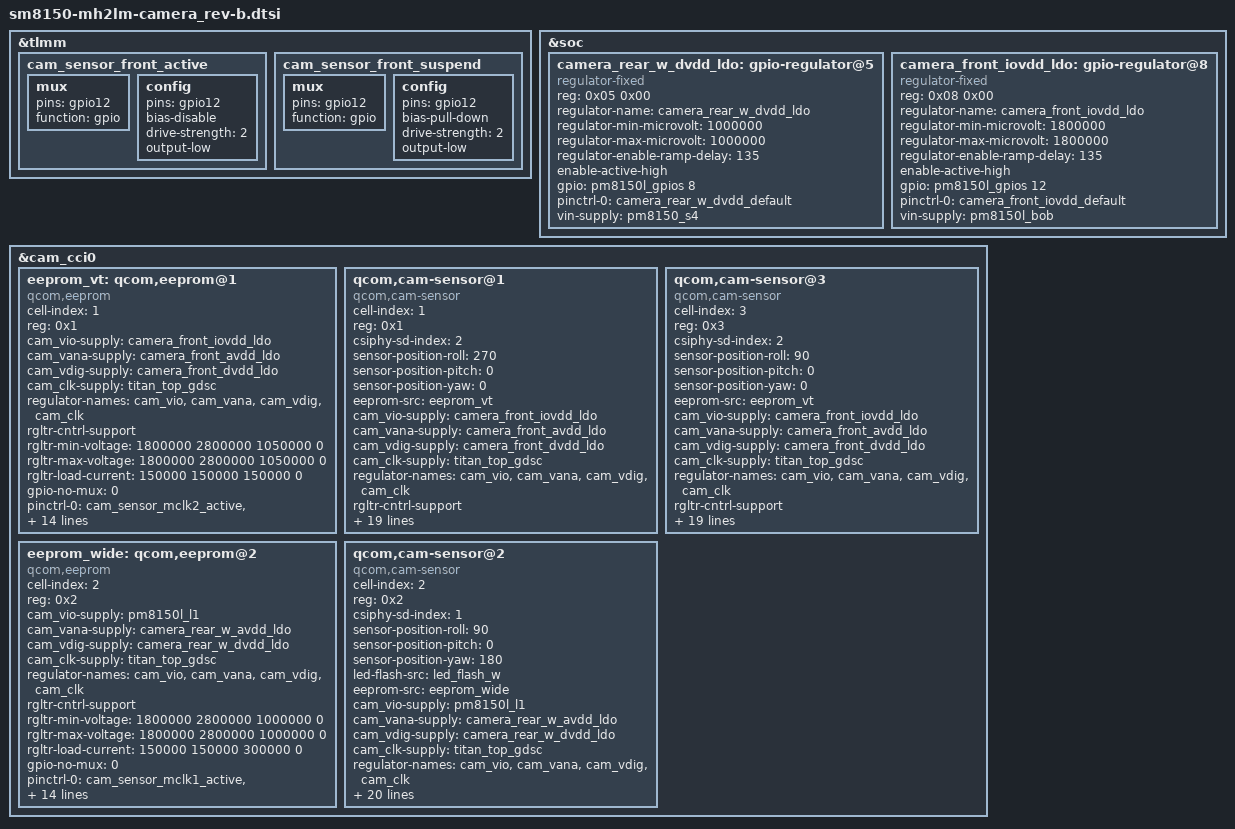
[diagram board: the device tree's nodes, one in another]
/*
 * Copyright (c) 2018, The Linux Foundation. All rights reserved.
 *
 * This program is free software; you can redistribute it and/or modify
 * it under the terms of the GNU General Public License version 2 and
 * only version 2 as published by the Free Software Foundation.
 *
 * This program is distributed in the hope that it will be useful,
 * but WITHOUT ANY WARRANTY; without even the implied warranty of
 * MERCHANTABILITY or FITNESS FOR A PARTICULAR PURPOSE.  See the
 * GNU General Public License for more details.
 */

#include "sm8150-mh2lm-camera_common.dtsi"

&tlmm {
	cam_sensor_front_active: cam_sensor_front_active {
		mux {
			pins = "gpio12";
			function = "gpio";
		};

		config {
			pins = "gpio12";
			bias-disable;
			drive-strength = <2>;
			output-low;
		};
	};

	cam_sensor_front_suspend: cam_sensor_front_suspend {
		mux {
			pins = "gpio12";
			function = "gpio";
		};

		config {
			pins = "gpio12";
			bias-pull-down;
			drive-strength = <2>;
			output-low;
		};
	};
};

&soc {
	camera_rear_w_dvdd_ldo: gpio-regulator@5 {
		compatible = "regulator-fixed";
		reg = <0x05 0x00>;
		regulator-name = "camera_rear_w_dvdd_ldo";
		regulator-min-microvolt = <1000000>;
		regulator-max-microvolt = <1000000>;
		regulator-enable-ramp-delay = <135>;
		enable-active-high;
		gpio = <&pm8150l_gpios 8 0>;
		pinctrl-names = "default";
		pinctrl-0 = <&camera_rear_w_dvdd_default>;
		vin-supply = <&pm8150_s4>;
	};

	camera_front_iovdd_ldo: gpio-regulator@8 {
		compatible = "regulator-fixed";
		reg = <0x08 0x00>;
		regulator-name = "camera_front_iovdd_ldo";
		regulator-min-microvolt = <1800000>;
		regulator-max-microvolt = <1800000>;
		regulator-enable-ramp-delay = <135>;
		enable-active-high;
		gpio = <&pm8150l_gpios 12 0>;
		pinctrl-names = "default";
		pinctrl-0 = <&camera_front_iovdd_default>;
		vin-supply = <&pm8150l_bob>;
	};
};

&cam_cci0 {
	eeprom_vt: qcom,eeprom@1 {
		cell-index = <1>;
		reg = <0x1>;
		compatible = "qcom,eeprom";
		cam_vio-supply =  <&camera_front_iovdd_ldo>;
		cam_vana-supply = <&camera_front_avdd_ldo>;
		cam_vdig-supply = <&camera_front_dvdd_ldo>;
		cam_clk-supply = <&titan_top_gdsc>;
		regulator-names = "cam_vio", "cam_vana", "cam_vdig", "cam_clk";
		rgltr-cntrl-support;
		rgltr-min-voltage = <1800000 2800000 1050000 0>;
		rgltr-max-voltage = <1800000 2800000 1050000 0>;
		rgltr-load-current = <150000 150000 150000 0>;
		gpio-no-mux = <0>;
		pinctrl-names = "cam_default", "cam_suspend";
		pinctrl-0 = <&cam_sensor_mclk2_active
				 &cam_sensor_front_active>;
		pinctrl-1 = <&cam_sensor_mclk2_suspend
				 &cam_sensor_front_suspend>;
		gpios = <&tlmm 15 0>,
			<&tlmm 12 0>;
		gpio-reset = <1>;
		gpio-req-tbl-num = <0 1>;
		gpio-req-tbl-flags = <1 0>;
		gpio-req-tbl-label = "VT_MCLK",
					"VT_RESET";
		sensor-mode = <0>;
		cci-device = <1>;
		cci-master = <0>;
		status = "ok";
		clocks = <&clock_camcc CAM_CC_MCLK2_CLK>;
		clock-names = "cam_clk";
		clock-cntl-level = "turbo";
		clock-rates = <19200000>;
    };

	qcom,cam-sensor@1 {
		cell-index = <1>;
		compatible = "qcom,cam-sensor";
		reg = <0x1>;
		csiphy-sd-index = <2>;
		sensor-position-roll = <270>;
		sensor-position-pitch = <0>;
		sensor-position-yaw = <0>;
		eeprom-src = <&eeprom_vt>;
		cam_vio-supply =  <&camera_front_iovdd_ldo>;
		cam_vana-supply = <&camera_front_avdd_ldo>;
		cam_vdig-supply = <&camera_front_dvdd_ldo>;
		cam_clk-supply = <&titan_top_gdsc>;
		regulator-names = "cam_vio", "cam_vana", "cam_vdig", "cam_clk";
		rgltr-cntrl-support;
		rgltr-min-voltage = <1800000 2800000 1050000 0>;
		rgltr-max-voltage = <1800000 2800000 1050000 0>;
		rgltr-load-current = <150000 150000 150000 0>;
		gpio-no-mux = <0>;
		pinctrl-names = "cam_default", "cam_suspend";
		pinctrl-0 = <&cam_sensor_mclk2_active
				 &cam_sensor_front_active>;
		pinctrl-1 = <&cam_sensor_mclk2_suspend
				 &cam_sensor_front_suspend>;
		gpios = <&tlmm 15 0>,
			<&tlmm 12 0>;
		gpio-reset = <1>;
		gpio-req-tbl-num = <0 1>;
		gpio-req-tbl-flags = <1 0>;
		gpio-req-tbl-label = "VT_MCLK",
					"VT_RESET";
		sensor-mode = <0>;
		cci-device = <1>;
		cci-master = <0>;
		status = "ok";
		clocks = <&clock_camcc CAM_CC_MCLK2_CLK>;
		clock-names = "cam_clk";
		clock-cntl-level = "turbo";
		clock-rates = <19200000>;
	};

	qcom,cam-sensor@3 {
		cell-index = <3>;
		compatible = "qcom,cam-sensor";
		reg = <0x3>;
		csiphy-sd-index = <2>;
		sensor-position-roll = <90>;
		sensor-position-pitch = <0>;
		sensor-position-yaw = <0>;
		eeprom-src = <&eeprom_vt>;
		cam_vio-supply =  <&camera_front_iovdd_ldo>;
		cam_vana-supply = <&camera_front_avdd_ldo>;
		cam_vdig-supply = <&camera_front_dvdd_ldo>;
		cam_clk-supply = <&titan_top_gdsc>;
		regulator-names = "cam_vio", "cam_vana", "cam_vdig", "cam_clk";
		rgltr-cntrl-support;
		rgltr-min-voltage = <1800000 2800000 1050000 0>;
		rgltr-max-voltage = <1800000 2800000 1050000 0>;
		rgltr-load-current = <150000 150000 150000 0>;
		gpio-no-mux = <0>;
		pinctrl-names = "cam_default", "cam_suspend";
		pinctrl-0 = <&cam_sensor_mclk2_active
				 &cam_sensor_front_active>;
		pinctrl-1 = <&cam_sensor_mclk2_suspend
				 &cam_sensor_front_suspend>;
		gpios = <&tlmm 15 0>,
			<&tlmm 12 0>;
		gpio-reset = <1>;
		gpio-req-tbl-num = <0 1>;
		gpio-req-tbl-flags = <1 0>;
		gpio-req-tbl-label = "VT_MCLK",
					"VT_RESET";
		sensor-mode = <0>;
		cci-device = <1>;
		cci-master = <0>;
		status = "ok";
		clocks = <&clock_camcc CAM_CC_MCLK2_CLK>;
		clock-names = "cam_clk";
		clock-cntl-level = "turbo";
		clock-rates = <19200000>;
	};

	eeprom_wide: qcom,eeprom@2 {
		cell-index = <2>;
		reg = <0x2>;
		compatible = "qcom,eeprom";
		cam_vio-supply = <&pm8150l_l1>;
		cam_vana-supply = <&camera_rear_w_avdd_ldo>;
		cam_vdig-supply = <&camera_rear_w_dvdd_ldo>;
		cam_clk-supply = <&titan_top_gdsc>;
		regulator-names = "cam_vio", "cam_vana", "cam_vdig", "cam_clk";
		rgltr-cntrl-support;
		rgltr-min-voltage = <1800000 2800000 1000000 0>;
		rgltr-max-voltage = <1800000 2800000 1000000 0>;
		rgltr-load-current = <150000 150000 300000 0>;
		gpio-no-mux = <0>;
		pinctrl-names = "cam_default", "cam_suspend";
		pinctrl-0 = <&cam_sensor_mclk1_active
				&cam_sensor_rear_w_active>;
		pinctrl-1 = <&cam_sensor_mclk1_suspend
				&cam_sensor_rear_w_suspend>;
		gpios = <&tlmm 14 0>,
			<&tlmm 30 0>;
		gpio-reset = <1>;
		gpio-req-tbl-num = <0 1>;
		gpio-req-tbl-flags = <1 0>;
		gpio-req-tbl-label = "CAMIF_MCLK1",
					"CAM_RESET1";
		sensor-mode = <0>;
		cci-device = <0>;
		cci-master = <1>;
		status = "ok";
		clocks = <&clock_camcc CAM_CC_MCLK1_CLK>;
		clock-names = "cam_clk";
		clock-cntl-level = "turbo";
		clock-rates = <19200000>;
	};

	qcom,cam-sensor@2 {
		cell-index = <2>;
		compatible = "qcom,cam-sensor";
		reg = <0x2>;
		csiphy-sd-index = <1>;
		sensor-position-roll = <90>;
		sensor-position-pitch = <0>;
		sensor-position-yaw = <180>;
		led-flash-src = <&led_flash_w>;
		eeprom-src = <&eeprom_wide>;
		cam_vio-supply = <&pm8150l_l1>;
		cam_vana-supply = <&camera_rear_w_avdd_ldo>;
		cam_vdig-supply = <&camera_rear_w_dvdd_ldo>;
		cam_clk-supply = <&titan_top_gdsc>;
		regulator-names = "cam_vio", "cam_vana", "cam_vdig", "cam_clk";
		rgltr-cntrl-support;
		rgltr-min-voltage = <1800000 2800000 1000000 0>;
		rgltr-max-voltage = <1800000 2800000 1000000 0>;
		rgltr-load-current = <150000 150000 300000 0>;
		gpio-no-mux = <0>;
		pinctrl-names = "cam_default", "cam_suspend";
		pinctrl-0 = <&cam_sensor_mclk1_active
				&cam_sensor_rear_w_active>;
		pinctrl-1 = <&cam_sensor_mclk1_suspend
				&cam_sensor_rear_w_suspend>;
		gpios = <&tlmm 14 0>,
			<&tlmm 30 0>;
		gpio-reset = <1>;
		gpio-req-tbl-num = <0 1>;
		gpio-req-tbl-flags = <1 0>;
		gpio-req-tbl-label = "CAMIF_MCLK1",
					"CAM_RESET1";
		sensor-mode = <0>;
		cci-device = <0>;
		cci-master = <1>;
		status = "ok";
		clocks = <&clock_camcc CAM_CC_MCLK1_CLK>;
		clock-names = "cam_clk";
		clock-cntl-level = "turbo";
		clock-rates = <19200000>;
	};
};
